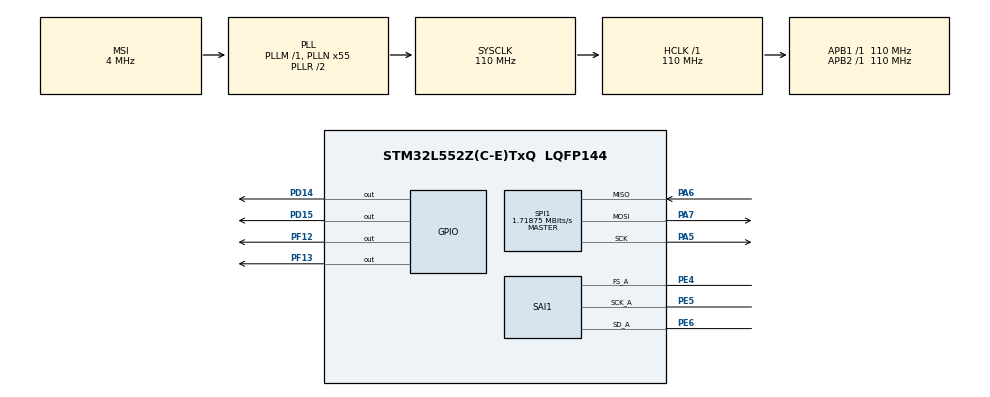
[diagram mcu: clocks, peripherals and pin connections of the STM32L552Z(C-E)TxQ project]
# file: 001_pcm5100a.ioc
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Dma.Request0=SAI1_A
Dma.SAI1_A.0.Channel_PRIV_NPRIV=DMA_CHANNEL_NPRIV_DISABLE
Dma.SAI1_A.0.Direction=DMA_MEMORY_TO_PERIPH
Dma.SAI1_A.0.EventEnable=DISABLE
Dma.SAI1_A.0.Instance=DMA1_Channel1
Dma.SAI1_A.0.MemDataAlignment=DMA_MDATAALIGN_WORD
Dma.SAI1_A.0.MemInc=DMA_MINC_ENABLE
Dma.SAI1_A.0.Mode=DMA_CIRCULAR
Dma.SAI1_A.0.PeriphDataAlignment=DMA_PDATAALIGN_WORD
Dma.SAI1_A.0.PeriphInc=DMA_PINC_DISABLE
Dma.SAI1_A.0.Polarity=HAL_DMAMUX_REQ_GEN_RISING
Dma.SAI1_A.0.Priority=DMA_PRIORITY_LOW
Dma.SAI1_A.0.RequestNumber=1
Dma.SAI1_A.0.SignalID=NONE
Dma.SAI1_A.0.SyncEnable=DISABLE
Dma.SAI1_A.0.SyncPolarity=HAL_DMAMUX_SYNC_NO_EVENT
Dma.SAI1_A.0.SyncRequestNumber=1
Dma.SAI1_A.0.SyncSignalID=NONE
Mcu.Family=STM32L5
Mcu.Name=STM32L552Z(C-E)TxQ
Mcu.Package=LQFP144
Mcu.TrustZone=disable
NUCLEO-L552ZE-Q.BUTTON=1
NUCLEO-L552ZE-Q.LD1=true
NUCLEO-L552ZE-Q.LD2=true
NUCLEO-L552ZE-Q.LD3=true
NUCLEO-L552ZE-Q.VCP=true
NVIC.DMA1_Channel1_IRQn=true\:0\:0\:false\:false\:true\:false\:true\:true
NVIC.EXTI13_IRQn=true\:0\:0\:false\:false\:true\:false\:true\:true
NVIC.PriorityGroup=NVIC_PRIORITYGROUP_3
NVIC.SPI1_IRQn=true\:0\:0\:false\:false\:true\:true\:true\:true
PA13\ (JTMS/SWDIO).Signal=DEBUG_JTMS-SWDIO
PA14\ (JTCK/SWCLK).Signal=DEBUG_JTCK-SWCLK
PA5.Mode=Full_Duplex_Master
PA5.Signal=SPI1_SCK
PA6.Mode=Full_Duplex_Master
PA6.Signal=SPI1_MISO
PA7.Mode=Full_Duplex_Master
PA7.Signal=SPI1_MOSI
PB3\ (JTDO/TRACESWO).Signal=DEBUG_JTDO-SWO
PC14-OSC32_IN\ (PC14).Signal=RCC_OSC32_IN
PC15-OSC32_OUT\ (PC15).Signal=RCC_OSC32_OUT
PD14.Signal=GPIO_Output
PD15.Signal=GPIO_Output
PE4.Mode=SAI_A_Master
PE4.Signal=SAI1_FS_A
PE5.Mode=SAI_A_Master
PE5.Signal=SAI1_SCK_A
PE6.Mode=SAI_A_Master
PE6.Signal=SAI1_SD_A
PF12.Signal=GPIO_Output
PF13.Signal=GPIO_Output
PG7.Signal=LPUART1_TX
PG8.Signal=LPUART1_RX
ProjectManager.HeapSize=0x200
ProjectManager.StackSize=0x400
ProjectManager.TargetToolchain=STM32CubeIDE
RCC.ADCCLockSelection=RCC_ADCCLKSOURCE_SYSCLK
RCC.ADCFreq_Value=110000000
RCC.AHBFreq_Value=110000000
RCC.APB1Freq_Value=110000000
RCC.APB1TimFreq_Value=110000000
RCC.APB2Freq_Value=110000000
RCC.APB2TimFreq_Value=110000000
RCC.CK48CLockSelection=RCC_USBCLKSOURCE_HSI48
RCC.CortexFreq_Value=110000000
RCC.HCLKFreq_Value=110000000
RCC.HSE_VALUE=8000000
RCC.HSI48_VALUE=48000000
RCC.HSI_VALUE=16000000
RCC.LSE_VALUE=32768
RCC.MSI_VALUE=4000000
RCC.PLLN=55
RCC.PLLSAI1N=24
RCC.RTCClockSelection=RCC_RTCCLKSOURCE_LSE
RCC.SYSCLKFreq_VALUE=110000000
RCC.SYSCLKSource=RCC_SYSCLKSOURCE_PLLCLK
RCC.USBFreq_Value=48000000
RCC.VCOOutputFreq_Value=220000000
SAI1.AudioFrequency-SAI_A_Master=SAI_AUDIO_FREQUENCY_96K
SAI1.ErrorAudioFreq-SAI_A_Master=-44.19 %
SAI1.InitProtocol-SAI_A_Master=Enable
SAI1.Instance-SAI_A_Master=SAI$Index_Block_A
SAI1.MckOutput-SAI_A_Master=SAI_MCK_OUTPUT_DISABLE
SAI1.RealAudioFreq-SAI_A_Master=53.571 KHz
SAI1.VirtualMode-SAI_A_Master=VM_MASTER
SAI1.VirtualProtocol-SAI_A_BASIC=VM_BASIC_PROTOCOL
SPI1.BaudRatePrescaler=SPI_BAUDRATEPRESCALER_64
SPI1.CLKPhase=SPI_PHASE_2EDGE
SPI1.CLKPolarity=SPI_POLARITY_HIGH
SPI1.CRCCalculation=SPI_CRCCALCULATION_DISABLE
SPI1.CalculateBaudRate=1.71875 MBits/s
SPI1.DataSize=SPI_DATASIZE_8BIT
SPI1.Direction=SPI_DIRECTION_2LINES
SPI1.Mode=SPI_MODE_MASTER
SPI1.VirtualType=VM_MASTER
VP_ICACHE_VS_ICACHE.Mode=DirectMappedCache
VP_NUCLEO-L552ZE-Q_VS_BSP_COMMON.Mode=COMMON
VP_PWR_VS_DBSignals.Mode=DisableDeadBatterySignals
VP_PWR_VS_SECSignals.Mode=Security/Privilege
VP_RNG_VS_RNG.Mode=RNG_Activate
VP_SAI1_VP_$IpInstance_SAIA_SAI_BASIC.Mode=SAI_A_BASIC
board=NUCLEO-L552ZE-Q

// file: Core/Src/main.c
/* USER CODE BEGIN Header */
/**
  ******************************************************************************
  * @file           : main.c
  * @brief          : Main program body
  ******************************************************************************
  * @attention
  *
  * Copyright (c) 2025 STMicroelectronics.
  * All rights reserved.
  *
  * This software is licensed under terms that can be found in the LICENSE file
  * in the root directory of this software component.
  * If no LICENSE file comes with this software, it is provided AS-IS.
  *
  ******************************************************************************
  */
/* USER CODE END Header */
#include "main.h"

/* USER CODE BEGIN Includes */
#include <stdio.h>
/* USER CODE END Includes */

COM_InitTypeDef BspCOMInit;

RNG_HandleTypeDef hrng;

SAI_HandleTypeDef hsai_BlockA1;
DMA_HandleTypeDef hdma_sai1_a;

SPI_HandleTypeDef hspi1;

void SystemClock_Config(void);
static void MX_GPIO_Init(void);
static void MX_DMA_Init(void);
static void MX_ICACHE_Init(void);
static void MX_SAI1_Init(void);
static void MX_SPI1_Init(void);
static void MX_RNG_Init(void);

int main(void)
{

  /* MCU Configuration--------------------------------------------------------*/

  /* Reset of all peripherals, Initializes the Flash interface and the Systick. */
  HAL_Init();

  /* Configure the system clock */
  SystemClock_Config();

  /* Initialize all configured peripherals */
  MX_GPIO_Init();
  MX_DMA_Init();
  MX_ICACHE_Init();
  MX_SAI1_Init();
  MX_SPI1_Init();
  MX_RNG_Init();

  /* Initialize leds */
  BSP_LED_Init(LED_GREEN);
  BSP_LED_Init(LED_BLUE);
  BSP_LED_Init(LED_RED);

  /* Initialize USER push-button, will be used to trigger an interrupt each time it's pressed.*/
  BSP_PB_Init(BUTTON_USER, BUTTON_MODE_EXTI);

  /* Initialize COM1 port (115200, 8 bits (7-bit data + 1 stop bit), no parity */
  BspCOMInit.BaudRate   = 115200;
  BspCOMInit.WordLength = COM_WORDLENGTH_8B;
  BspCOMInit.StopBits   = COM_STOPBITS_1;
  BspCOMInit.Parity     = COM_PARITY_NONE;
  BspCOMInit.HwFlowCtl  = COM_HWCONTROL_NONE;
  if (BSP_COM_Init(COM1, &BspCOMInit) != BSP_ERROR_NONE)
  {
    Error_Handler();
  }

  /* Infinite loop */
  /* USER CODE BEGIN WHILE */

  while (1)
  {
	  printf("hola mundo\n\r");
	  HAL_Delay(200);
    /* USER CODE END WHILE */

  }
}

void SystemClock_Config(void)
{
  RCC_OscInitTypeDef RCC_OscInitStruct = {0};
  RCC_ClkInitTypeDef RCC_ClkInitStruct = {0};

  /** Configure the main internal regulator output voltage
  */
  if (HAL_PWREx_ControlVoltageScaling(PWR_REGULATOR_VOLTAGE_SCALE0) != HAL_OK)
  {
    Error_Handler();
  }

  /** Initializes the RCC Oscillators according to the specified parameters
  * in the RCC_OscInitTypeDef structure.
  */
  RCC_OscInitStruct.OscillatorType = RCC_OSCILLATORTYPE_HSI48|RCC_OSCILLATORTYPE_MSI;
  RCC_OscInitStruct.HSI48State = RCC_HSI48_ON;
  RCC_OscInitStruct.MSIState = RCC_MSI_ON;
  RCC_OscInitStruct.MSICalibrationValue = RCC_MSICALIBRATION_DEFAULT;
  RCC_OscInitStruct.MSIClockRange = RCC_MSIRANGE_6;
  RCC_OscInitStruct.PLL.PLLState = RCC_PLL_ON;
  RCC_OscInitStruct.PLL.PLLSource = RCC_PLLSOURCE_MSI;
  RCC_OscInitStruct.PLL.PLLM = 1;
  RCC_OscInitStruct.PLL.PLLN = 55;
  RCC_OscInitStruct.PLL.PLLP = RCC_PLLP_DIV7;
  RCC_OscInitStruct.PLL.PLLQ = RCC_PLLQ_DIV2;
  RCC_OscInitStruct.PLL.PLLR = RCC_PLLR_DIV2;
  if (HAL_RCC_OscConfig(&RCC_OscInitStruct) != HAL_OK)
  {
    Error_Handler();
  }

  /** Initializes the CPU, AHB and APB buses clocks
  */
  RCC_ClkInitStruct.ClockType = RCC_CLOCKTYPE_HCLK|RCC_CLOCKTYPE_SYSCLK
                              |RCC_CLOCKTYPE_PCLK1|RCC_CLOCKTYPE_PCLK2;
  RCC_ClkInitStruct.SYSCLKSource = RCC_SYSCLKSOURCE_PLLCLK;
  RCC_ClkInitStruct.AHBCLKDivider = RCC_SYSCLK_DIV1;
  RCC_ClkInitStruct.APB1CLKDivider = RCC_HCLK_DIV1;
  RCC_ClkInitStruct.APB2CLKDivider = RCC_HCLK_DIV1;

  if (HAL_RCC_ClockConfig(&RCC_ClkInitStruct, FLASH_LATENCY_5) != HAL_OK)
  {
    Error_Handler();
  }
}

static void MX_ICACHE_Init(void)
{

  /** Enable instruction cache in 1-way (direct mapped cache)
  */
  if (HAL_ICACHE_ConfigAssociativityMode(ICACHE_1WAY) != HAL_OK)
  {
    Error_Handler();
  }
  if (HAL_ICACHE_Enable() != HAL_OK)
  {
    Error_Handler();
  }

}

static void MX_RNG_Init(void)
{

  hrng.Instance = RNG;
  hrng.Init.ClockErrorDetection = RNG_CED_ENABLE;
  if (HAL_RNG_Init(&hrng) != HAL_OK)
  {
    Error_Handler();
  }

}

static void MX_SAI1_Init(void)
{

  hsai_BlockA1.Instance = SAI1_Block_A;
  hsai_BlockA1.Init.AudioMode = SAI_MODEMASTER_TX;
  hsai_BlockA1.Init.Synchro = SAI_ASYNCHRONOUS;
  hsai_BlockA1.Init.OutputDrive = SAI_OUTPUTDRIVE_DISABLE;
  hsai_BlockA1.Init.NoDivider = SAI_MASTERDIVIDER_ENABLE;
  hsai_BlockA1.Init.FIFOThreshold = SAI_FIFOTHRESHOLD_EMPTY;
  hsai_BlockA1.Init.AudioFrequency = SAI_AUDIO_FREQUENCY_96K;
  hsai_BlockA1.Init.SynchroExt = SAI_SYNCEXT_DISABLE;
  hsai_BlockA1.Init.MonoStereoMode = SAI_STEREOMODE;
  hsai_BlockA1.Init.CompandingMode = SAI_NOCOMPANDING;
  hsai_BlockA1.Init.TriState = SAI_OUTPUT_NOTRELEASED;
  if (HAL_SAI_InitProtocol(&hsai_BlockA1, SAI_I2S_STANDARD, SAI_PROTOCOL_DATASIZE_16BIT, 2) != HAL_OK)
  {
    Error_Handler();
  }

}

static void MX_SPI1_Init(void)
{

  /* SPI1 parameter configuration*/
  hspi1.Instance = SPI1;
  hspi1.Init.Mode = SPI_MODE_MASTER;
  hspi1.Init.Direction = SPI_DIRECTION_2LINES;
  hspi1.Init.DataSize = SPI_DATASIZE_8BIT;
  hspi1.Init.CLKPolarity = SPI_POLARITY_HIGH;
  hspi1.Init.CLKPhase = SPI_PHASE_2EDGE;
  hspi1.Init.NSS = SPI_NSS_SOFT;
  hspi1.Init.BaudRatePrescaler = SPI_BAUDRATEPRESCALER_64;
  hspi1.Init.FirstBit = SPI_FIRSTBIT_MSB;
  hspi1.Init.TIMode = SPI_TIMODE_DISABLE;
  hspi1.Init.CRCCalculation = SPI_CRCCALCULATION_DISABLE;
  hspi1.Init.CRCPolynomial = 7;
  hspi1.Init.CRCLength = SPI_CRC_LENGTH_DATASIZE;
  hspi1.Init.NSSPMode = SPI_NSS_PULSE_DISABLE;
  if (HAL_SPI_Init(&hspi1) != HAL_OK)
  {
    Error_Handler();
  }

}

static void MX_DMA_Init(void)
{

  /* DMA controller clock enable */
  __HAL_RCC_DMAMUX1_CLK_ENABLE();
  __HAL_RCC_DMA1_CLK_ENABLE();

  /* DMA interrupt init */
  /* DMA1_Channel1_IRQn interrupt configuration */
  HAL_NVIC_SetPriority(DMA1_Channel1_IRQn, 0, 0);
  HAL_NVIC_EnableIRQ(DMA1_Channel1_IRQn);

}

static void MX_GPIO_Init(void)
{
  GPIO_InitTypeDef GPIO_InitStruct = {0};

  /* GPIO Ports Clock Enable */
  __HAL_RCC_GPIOE_CLK_ENABLE();
  __HAL_RCC_GPIOC_CLK_ENABLE();
  __HAL_RCC_GPIOA_CLK_ENABLE();
  __HAL_RCC_GPIOF_CLK_ENABLE();
  __HAL_RCC_GPIOD_CLK_ENABLE();
  __HAL_RCC_GPIOB_CLK_ENABLE();

  /*Configure GPIO pin Output Level */
  HAL_GPIO_WritePin(GPIOF, GPIO_PIN_12|GPIO_PIN_13, GPIO_PIN_RESET);

  /*Configure GPIO pin Output Level */
  HAL_GPIO_WritePin(GPIOD, GPIO_PIN_14|GPIO_PIN_15, GPIO_PIN_RESET);

  /*Configure GPIO pins : PF12 PF13 */
  GPIO_InitStruct.Pin = GPIO_PIN_12|GPIO_PIN_13;
  GPIO_InitStruct.Mode = GPIO_MODE_OUTPUT_PP;
  GPIO_InitStruct.Pull = GPIO_NOPULL;
  GPIO_InitStruct.Speed = GPIO_SPEED_FREQ_LOW;
  HAL_GPIO_Init(GPIOF, &GPIO_InitStruct);

  /*Configure GPIO pins : PD14 PD15 */
  GPIO_InitStruct.Pin = GPIO_PIN_14|GPIO_PIN_15;
  GPIO_InitStruct.Mode = GPIO_MODE_OUTPUT_PP;
  GPIO_InitStruct.Pull = GPIO_NOPULL;
  GPIO_InitStruct.Speed = GPIO_SPEED_FREQ_LOW;
  HAL_GPIO_Init(GPIOD, &GPIO_InitStruct);

}

void Error_Handler(void)
{
  __disable_irq();
  while (1)
  {
  }
}
